# M3HP register map
File version: 0.1
Registers are 32-bit, read-write, reset 0x0 unless marked. A register's access mark holds for its fields unless they carry their own. Offsets are from the block's base; [hi:lo] are bit positions; {n}, {i} and the like mark numbered series.

## PF — Port F
Base 0x400C0500
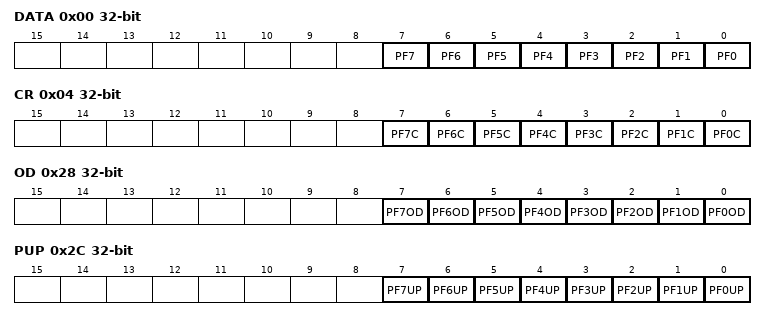
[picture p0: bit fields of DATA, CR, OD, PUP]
0x00 DATA — PF Data Register
  [n] PF{n} (n=0..7)
0x04 CR — PF Control Register
  [n] PF{n}C (n=0..7)
0x28 OD — PF Open Drain Control Register
  [n] PF{n}OD (n=0..7)
0x2C PUP — PF Pull-up Control Register
  [n] PF{n}UP (n=0..7)
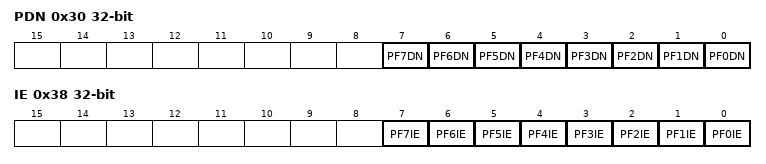
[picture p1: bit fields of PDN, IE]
0x30 PDN — PF Pull-Down Control Register
  [n] PF{n}DN (n=0..7)
0x38 IE — PF Input Enable Control Register
  [n] PF{n}IE (n=0..7)

## PG — Port G
Base 0x400C0600
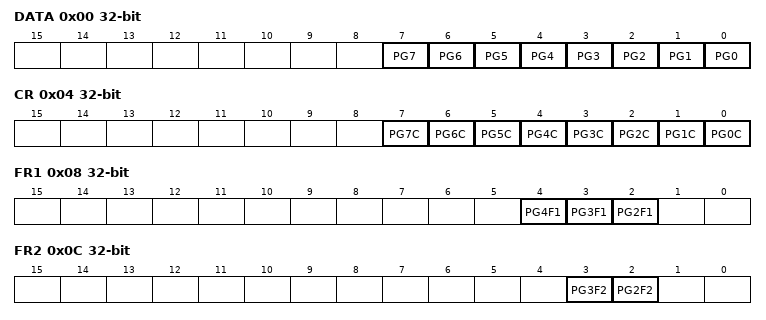
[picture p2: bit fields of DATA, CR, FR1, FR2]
0x00 DATA — PG Data Register
  [n] PG{n} (n=0..7)
0x04 CR — PG Control Register
  [n] PG{n}C (n=0..7)
0x08 FR1 — PG Function Register 1
  [4] PG4F1, [3] PG3F1, [2] PG2F1
0x0C FR2 — PG Function Register 2
  [3] PG3F2, [2] PG2F2
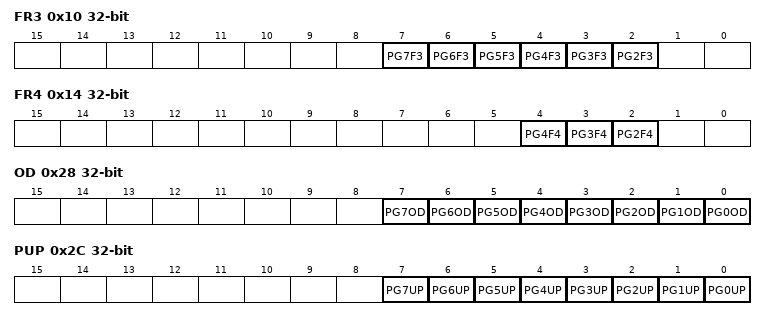
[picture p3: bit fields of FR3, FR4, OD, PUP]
0x10 FR3 — PG Function Register 3
  [n] PG{n}F3 (n=2..7)
0x14 FR4 — PG Function Register 4
  [4] PG4F4, [3] PG3F4, [2] PG2F4
0x28 OD — PG Open Drain Control Register
  [n] PG{n}OD (n=0..7)
0x2C PUP — PG Pull-up Control Register
  [n] PG{n}UP (n=0..7)
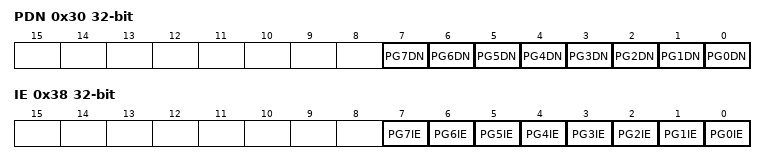
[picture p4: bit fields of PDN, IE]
0x30 PDN — PG Pull-Down Control Register
  [n] PG{n}DN (n=0..7)
0x38 IE — PG Input Enable Control Register
  [n] PG{n}IE (n=0..7)

## PH — Port H
Base 0x400C0700
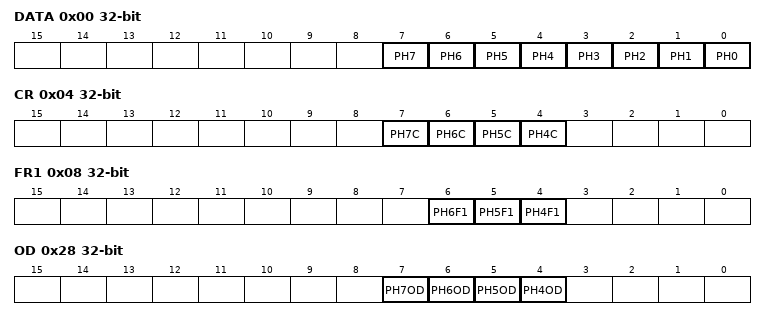
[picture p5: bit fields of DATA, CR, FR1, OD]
0x00 DATA — PH Data Register
  [n] PH{n} (n=0..7)
0x04 CR — PH Control Register
  [n] PH{n}C (n=4..7)
0x08 FR1 — PH Function Register 1
  [6] PH6F1, [5] PH5F1, [4] PH4F1
0x28 OD — PH Open Drain Control Register
  [n] PH{n}OD (n=4..7)
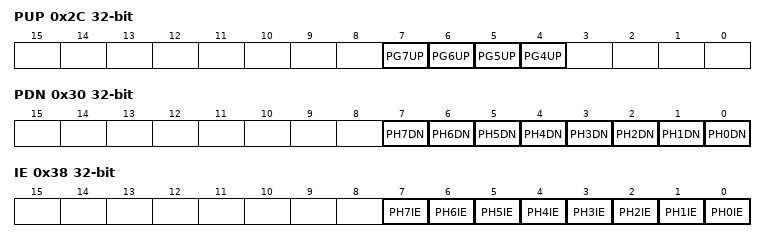
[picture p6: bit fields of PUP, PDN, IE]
0x2C PUP — PH Pull-up Control Register
  [n] PG{n}UP (n=4..7)
0x30 PDN — PH Pull-Down Control Register
  [n] PH{n}DN (n=0..7)
0x38 IE — PH Input Enable Control Register
  [n] PH{n}IE (n=0..7)

## PJ — Port J
Base 0x400C0800
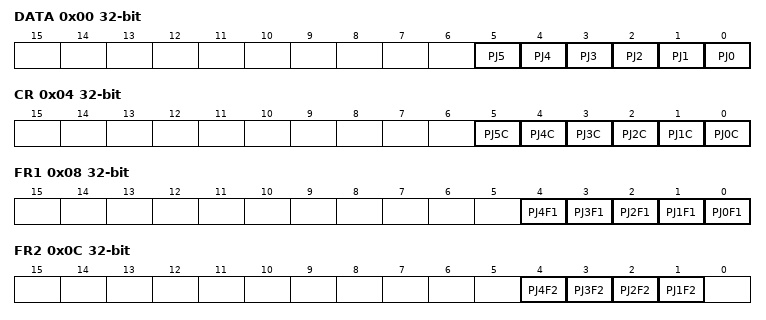
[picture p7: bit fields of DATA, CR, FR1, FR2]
0x00 DATA — PJ Data Register
  [n] PJ{n} (n=0..5)
0x04 CR — PJ Control Register
  [n] PJ{n}C (n=0..5)
0x08 FR1 — PJ Function Register 1
  [n] PJ{n}F1 (n=0..4)
0x0C FR2 — PJ Function Register 2
  [n] PJ{n}F2 (n=1..4)
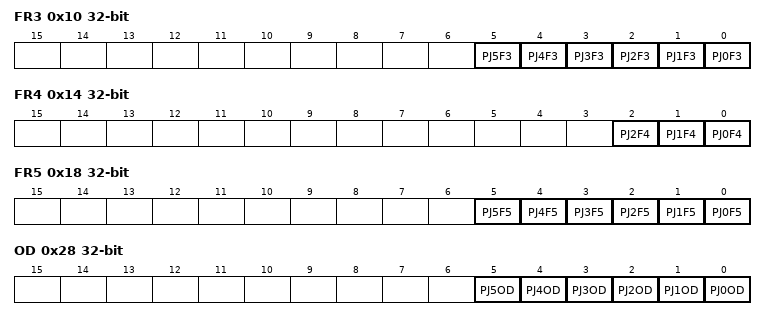
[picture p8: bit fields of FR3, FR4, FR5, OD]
0x10 FR3 — PJ Function Register 3
  [n] PJ{n}F3 (n=0..5)
0x14 FR4 — PJ Function Register 4
  [2] PJ2F4, [1] PJ1F4, [0] PJ0F4
0x18 FR5 — PJ Function Register 5
  [n] PJ{n}F5 (n=0..5)
0x28 OD — PJ Open Drain Control Register
  [n] PJ{n}OD (n=0..5)
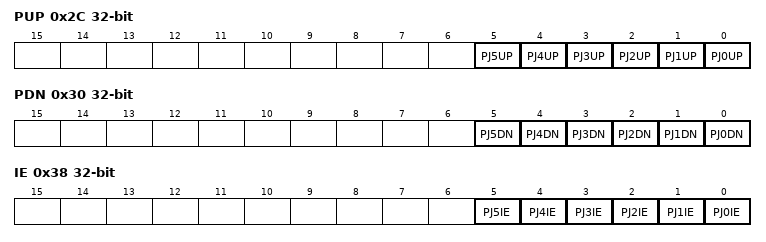
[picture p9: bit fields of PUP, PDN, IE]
0x2C PUP — PJ Pull-up Control Register
  [n] PJ{n}UP (n=0..5)
0x30 PDN — PJ Pull-Down Control Register
  [n] PJ{n}DN (n=0..5)
0x38 IE — PJ Input Enable Control Register
  [n] PJ{n}IE (n=0..5)

## PK — Port K
Base 0x400C0900
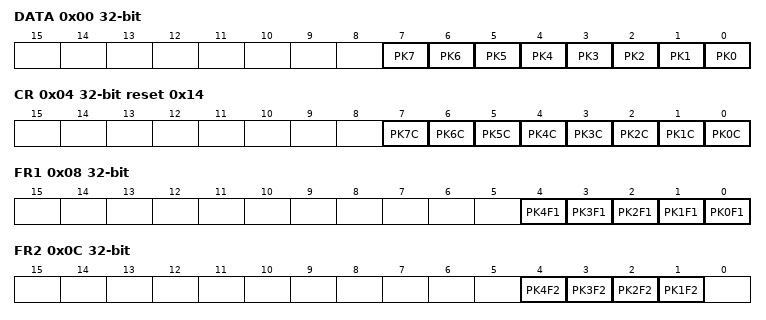
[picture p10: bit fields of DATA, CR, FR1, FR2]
0x00 DATA — PK Data Register
  [n] PK{n} (n=0..7)
0x04 CR reset 0x14 — PK Control Register
  [n] PK{n}C (n=0..7)
0x08 FR1 — PK Function Register 1
  [n] PK{n}F1 (n=0..4)
0x0C FR2 — PK Function Register 2
  [n] PK{n}F2 (n=1..4)
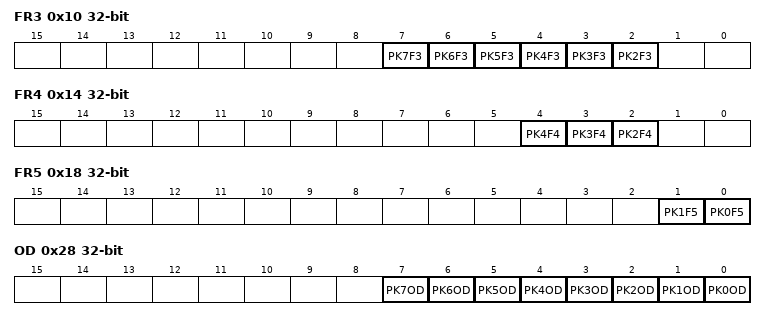
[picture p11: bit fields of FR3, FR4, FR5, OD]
0x10 FR3 — PK Function Register 3
  [n] PK{n}F3 (n=2..7)
0x14 FR4 — PK Function Register 4
  [4] PK4F4, [3] PK3F4, [2] PK2F4
0x18 FR5 — PK Function Register 5
  [1] PK1F5, [0] PK0F5
0x28 OD — PK Open Drain Control Register
  [n] PK{n}OD (n=0..7)
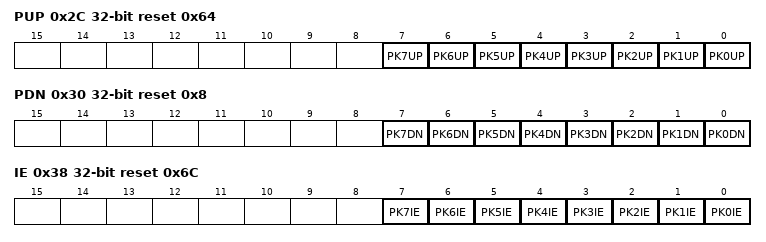
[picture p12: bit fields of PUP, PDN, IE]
0x2C PUP reset 0x64 — PK Pull-up Control Register
  [n] PK{n}UP (n=0..7)
0x30 PDN reset 0x8 — PK Pull-Down Control Register
  [n] PK{n}DN (n=0..7)
0x38 IE reset 0x6C — PK Input Enable Control Register
  [n] PK{n}IE (n=0..7)

## PL — Port L
Base 0x400C0A00
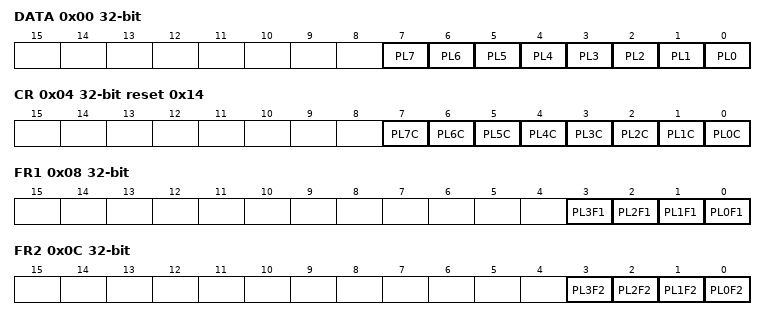
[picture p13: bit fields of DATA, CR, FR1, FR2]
0x00 DATA — PL Data Register
  [n] PL{n} (n=0..7)
0x04 CR reset 0x14 — PL Control Register
  [n] PL{n}C (n=0..7)
0x08 FR1 — PL Function Register 1
  [n] PL{n}F1 (n=0..3)
0x0C FR2 — PL Function Register 2
  [n] PL{n}F2 (n=0..3)
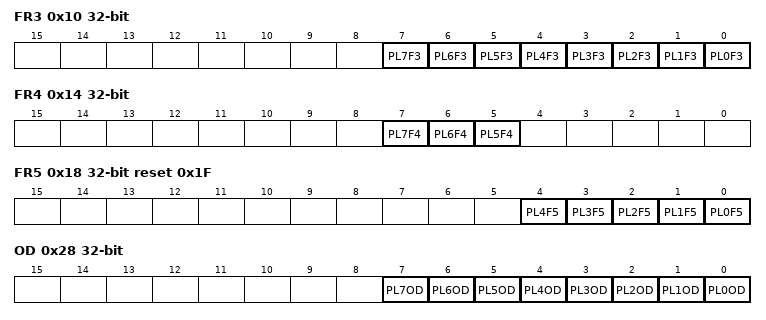
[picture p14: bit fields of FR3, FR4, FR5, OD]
0x10 FR3 — PL Function Register 3
  [n] PL{n}F3 (n=0..7)
0x14 FR4 — PL Function Register 4
  [7] PL7F4, [6] PL6F4, [5] PL5F4
0x18 FR5 reset 0x1F — PL Function Register 4
  [n] PL{n}F5 (n=0..4)
0x28 OD — PL Open Drain Control Register
  [n] PL{n}OD (n=0..7)
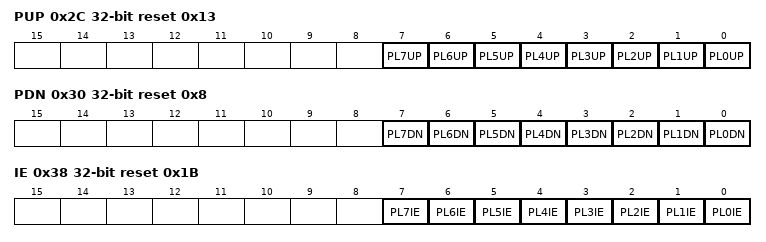
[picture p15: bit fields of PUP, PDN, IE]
0x2C PUP reset 0x13 — PL Pull-up Control Register
  [n] PL{n}UP (n=0..7)
0x30 PDN reset 0x8 — PL Pull-Down Control Register
  [n] PL{n}DN (n=0..7)
0x38 IE reset 0x1B — PL Input Enable Control Register
  [n] PL{n}IE (n=0..7)
